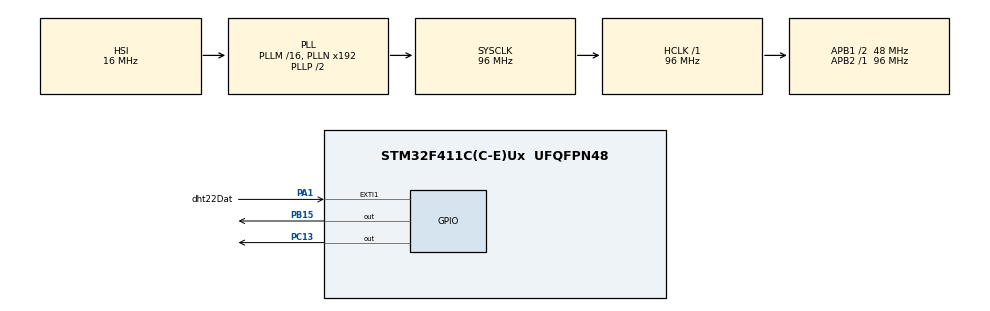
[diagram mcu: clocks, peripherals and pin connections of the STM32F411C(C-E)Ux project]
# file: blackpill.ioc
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FREERTOS.Tasks01=defaultTask,0,128,StartDefaultTask,Default,NULL,Dynamic,NULL,NULL
Mcu.Family=STM32F4
Mcu.Name=STM32F411C(C-E)Ux
Mcu.Package=UFQFPN48
NVIC.EXTI1_IRQn=true\:5\:0\:false\:false\:true\:true\:true\:true\:true
NVIC.PriorityGroup=NVIC_PRIORITYGROUP_4
NVIC.TIM4_IRQn=true\:5\:0\:false\:false\:true\:true\:true\:true\:true
NVIC.TIM5_IRQn=true\:15\:0\:false\:false\:true\:false\:false\:true\:true
NVIC.TimeBase=TIM5_IRQn
NVIC.TimeBaseIP=TIM5
PA1.GPIO_Label=dht22Dat
PA1.GPIO_ModeDefaultEXTI=GPIO_MODE_IT_RISING_FALLING
PA1.Signal=GPXTI1
PA13.Mode=Serial_Wire
PA13.Signal=SYS_JTMS-SWDIO
PA14.Mode=Serial_Wire
PA14.Signal=SYS_JTCK-SWCLK
PB15.PinState=GPIO_PIN_SET
PB15.Signal=GPIO_Output
PC13-ANTI_TAMP.Signal=GPIO_Output
ProjectManager.HeapSize=0x200
ProjectManager.StackSize=0x400
ProjectManager.TargetToolchain=CMake
RCC.48MHZClocksFreq_Value=48000000
RCC.AHBFreq_Value=96000000
RCC.APB1CLKDivider=RCC_HCLK_DIV2
RCC.APB1Freq_Value=48000000
RCC.APB1TimFreq_Value=96000000
RCC.APB2Freq_Value=96000000
RCC.APB2TimFreq_Value=96000000
RCC.CortexFreq_Value=96000000
RCC.HCLKFreq_Value=96000000
RCC.HSE_VALUE=25000000
RCC.HSI_VALUE=16000000
RCC.LSE_VALUE=32768
RCC.SYSCLKFreq_VALUE=96000000
RCC.SYSCLKSource=RCC_SYSCLKSOURCE_PLLCLK
RCC.VCOOutputFreq_Value=192000000
VP_FREERTOS_VS_CMSIS_V1.Mode=CMSIS_V1
VP_SYS_VS_tim5.Mode=TIM5
VP_TIM4_VS_ClockSourceINT.Mode=Internal
board=custom

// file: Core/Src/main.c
/* USER CODE BEGIN Header */
/**
  ******************************************************************************
  * @file           : main.c
  * @brief          : Main program body
  ******************************************************************************
  * @attention
  *
  * Copyright (c) 2025 STMicroelectronics.
  * All rights reserved.
  *
  * This software is licensed under terms that can be found in the LICENSE file
  * in the root directory of this software component.
  * If no LICENSE file comes with this software, it is provided AS-IS.
  *
  ******************************************************************************
  */
/* USER CODE END Header */
#include "main.h"
#include "cmsis_os.h"
#include "tim.h"
#include "gpio.h"

/* USER CODE BEGIN Includes */
#include "app_main.h"
/* USER CODE END Includes */

void SystemClock_Config(void);
void MX_FREERTOS_Init(void);

int main(void)
{

  /* MCU Configuration--------------------------------------------------------*/

  /* Reset of all peripherals, Initializes the Flash interface and the Systick. */
  HAL_Init();

  /* Configure the system clock */
  SystemClock_Config();

  /* Initialize all configured peripherals */
  MX_GPIO_Init();
  MX_TIM4_Init();
  /* USER CODE BEGIN 2 */
    app_main_init();
  /* USER CODE END 2 */

  /* Call init function for freertos objects (in cmsis_os2.c) */
  MX_FREERTOS_Init();

  /* Start scheduler */
  osKernelStart();

  /* We should never get here as control is now taken by the scheduler */

  /* Infinite loop */
  while (1)
  {

  }
}

void SystemClock_Config(void)
{
  RCC_OscInitTypeDef RCC_OscInitStruct = {0};
  RCC_ClkInitTypeDef RCC_ClkInitStruct = {0};

  /** Configure the main internal regulator output voltage
  */
  __HAL_RCC_PWR_CLK_ENABLE();
  __HAL_PWR_VOLTAGESCALING_CONFIG(PWR_REGULATOR_VOLTAGE_SCALE1);

  /** Initializes the RCC Oscillators according to the specified parameters
  * in the RCC_OscInitTypeDef structure.
  */
  RCC_OscInitStruct.OscillatorType = RCC_OSCILLATORTYPE_HSI;
  RCC_OscInitStruct.HSIState = RCC_HSI_ON;
  RCC_OscInitStruct.HSICalibrationValue = RCC_HSICALIBRATION_DEFAULT;
  RCC_OscInitStruct.PLL.PLLState = RCC_PLL_ON;
  RCC_OscInitStruct.PLL.PLLSource = RCC_PLLSOURCE_HSI;
  RCC_OscInitStruct.PLL.PLLM = 16;
  RCC_OscInitStruct.PLL.PLLN = 192;
  RCC_OscInitStruct.PLL.PLLP = RCC_PLLP_DIV2;
  RCC_OscInitStruct.PLL.PLLQ = 4;
  if (HAL_RCC_OscConfig(&RCC_OscInitStruct) != HAL_OK)
  {
    Error_Handler();
  }

  /** Initializes the CPU, AHB and APB buses clocks
  */
  RCC_ClkInitStruct.ClockType = RCC_CLOCKTYPE_HCLK|RCC_CLOCKTYPE_SYSCLK
                              |RCC_CLOCKTYPE_PCLK1|RCC_CLOCKTYPE_PCLK2;
  RCC_ClkInitStruct.SYSCLKSource = RCC_SYSCLKSOURCE_PLLCLK;
  RCC_ClkInitStruct.AHBCLKDivider = RCC_SYSCLK_DIV1;
  RCC_ClkInitStruct.APB1CLKDivider = RCC_HCLK_DIV2;
  RCC_ClkInitStruct.APB2CLKDivider = RCC_HCLK_DIV1;

  if (HAL_RCC_ClockConfig(&RCC_ClkInitStruct, FLASH_LATENCY_3) != HAL_OK)
  {
    Error_Handler();
  }
}

void HAL_TIM_PeriodElapsedCallback(TIM_HandleTypeDef *htim)
{
  if (htim->Instance == TIM5)
  {
    HAL_IncTick();
  }
}

void Error_Handler(void)
{
  __disable_irq();
  while (1)
  {
  }
}

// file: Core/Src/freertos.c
/* USER CODE BEGIN Header */
/**
  ******************************************************************************
  * File Name          : freertos.c
  * Description        : Code for freertos applications
  ******************************************************************************
  * @attention
  *
  * Copyright (c) 2025 STMicroelectronics.
  * All rights reserved.
  *
  * This software is licensed under terms that can be found in the LICENSE file
  * in the root directory of this software component.
  * If no LICENSE file comes with this software, it is provided AS-IS.
  *
  ******************************************************************************
  */
/* USER CODE END Header */

#include "FreeRTOS.h"
#include "task.h"
#include "main.h"
#include "cmsis_os.h"

/* USER CODE BEGIN Includes */
#include "app_main.h"
/* USER CODE END Includes */

osThreadId defaultTaskHandle;

void StartDefaultTask(void const * argument);

void MX_FREERTOS_Init(void); /* (MISRA C 2004 rule 8.1) */

/* GetIdleTaskMemory prototype (linked to static allocation support) */
void vApplicationGetIdleTaskMemory( StaticTask_t **ppxIdleTaskTCBBuffer, StackType_t **ppxIdleTaskStackBuffer, uint32_t *pulIdleTaskStackSize );

/* USER CODE BEGIN GET_IDLE_TASK_MEMORY */
static StaticTask_t xIdleTaskTCBBuffer;
static StackType_t xIdleStack[configMINIMAL_STACK_SIZE];

void vApplicationGetIdleTaskMemory( StaticTask_t **ppxIdleTaskTCBBuffer, StackType_t **ppxIdleTaskStackBuffer, uint32_t *pulIdleTaskStackSize )
{
  *ppxIdleTaskTCBBuffer = &xIdleTaskTCBBuffer;
  *ppxIdleTaskStackBuffer = &xIdleStack[0];
  *pulIdleTaskStackSize = configMINIMAL_STACK_SIZE;
  /* place for user code */
}
/* USER CODE END GET_IDLE_TASK_MEMORY */

void MX_FREERTOS_Init(void) {

  /* Create the thread(s) */
  /* definition and creation of defaultTask */
  osThreadDef(defaultTask, StartDefaultTask, osPriorityNormal, 0, 128);
  defaultTaskHandle = osThreadCreate(osThread(defaultTask), NULL);

  /* USER CODE BEGIN RTOS_THREADS */
  freertos_tasks_init();
  /* USER CODE END RTOS_THREADS */

}

void StartDefaultTask(void const * argument)
{
  for(;;)
  {
    osDelay(1);
  }
}
